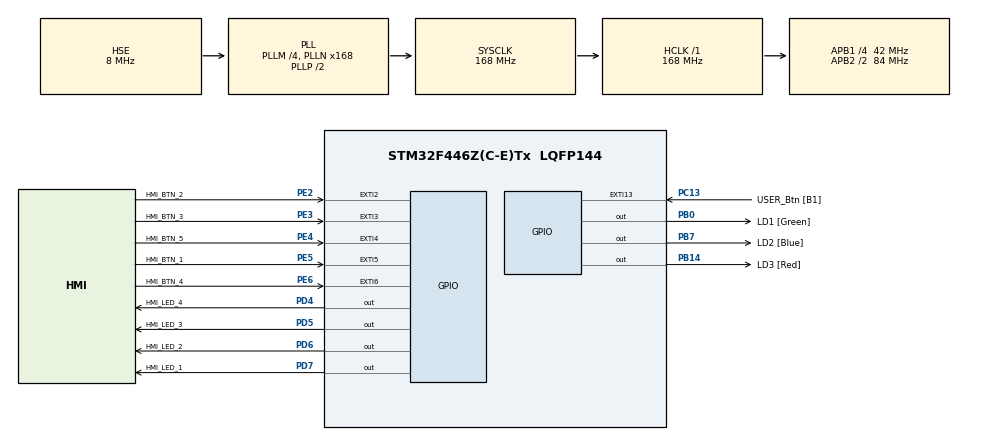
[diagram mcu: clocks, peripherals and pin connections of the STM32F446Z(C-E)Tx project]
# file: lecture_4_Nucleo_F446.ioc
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Mcu.Family=STM32F4
Mcu.Name=STM32F446Z(C-E)Tx
Mcu.Package=LQFP144
NVIC.EXTI15_10_IRQn=true\:0\:0\:false\:false\:true\:true\:true\:true
NVIC.EXTI2_IRQn=true\:0\:0\:false\:false\:true\:true\:true\:true
NVIC.EXTI3_IRQn=true\:0\:0\:false\:false\:true\:true\:true\:true
NVIC.EXTI4_IRQn=true\:0\:0\:false\:false\:true\:true\:true\:true
NVIC.EXTI9_5_IRQn=true\:0\:0\:false\:false\:true\:true\:true\:true
NVIC.PriorityGroup=NVIC_PRIORITYGROUP_4
PA13.Mode=Serial_Wire
PA13.Signal=SYS_JTMS-SWDIO
PA14.Mode=Serial_Wire
PA14.Signal=SYS_JTCK-SWCLK
PB0.GPIO_Label=LD1 [Green]
PB0.Signal=GPIO_Output
PB14.GPIO_Label=LD3 [Red]
PB14.Signal=GPIO_Output
PB7.GPIO_Label=LD2 [Blue]
PB7.Signal=GPIO_Output
PC13.GPIO_Label=USER_Btn [B1]
PC13.GPIO_ModeDefaultEXTI=GPIO_MODE_IT_RISING_FALLING
PC13.Signal=GPXTI13
PC14-OSC32_IN.Mode=LSE-External-Oscillator
PC14-OSC32_IN.Signal=RCC_OSC32_IN
PC15-OSC32_OUT.Mode=LSE-External-Oscillator
PC15-OSC32_OUT.Signal=RCC_OSC32_OUT
PD4.GPIO_Label=HMI_LED_4
PD4.GPIO_ModeDefaultOutputPP=GPIO_MODE_OUTPUT_PP
PD4.GPIO_PuPd=GPIO_NOPULL
PD4.GPIO_Speed=GPIO_SPEED_FREQ_LOW
PD4.PinState=GPIO_PIN_RESET
PD4.Signal=GPIO_Output
PD5.GPIO_Label=HMI_LED_3
PD5.GPIO_ModeDefaultOutputPP=GPIO_MODE_OUTPUT_PP
PD5.GPIO_PuPd=GPIO_NOPULL
PD5.GPIO_Speed=GPIO_SPEED_FREQ_LOW
PD5.PinState=GPIO_PIN_RESET
PD5.Signal=GPIO_Output
PD6.GPIO_Label=HMI_LED_2
PD6.GPIO_ModeDefaultOutputPP=GPIO_MODE_OUTPUT_PP
PD6.GPIO_PuPd=GPIO_NOPULL
PD6.GPIO_Speed=GPIO_SPEED_FREQ_LOW
PD6.PinState=GPIO_PIN_RESET
PD6.Signal=GPIO_Output
PD7.GPIO_Label=HMI_LED_1
PD7.GPIO_ModeDefaultOutputPP=GPIO_MODE_OUTPUT_PP
PD7.GPIO_PuPd=GPIO_NOPULL
PD7.GPIO_Speed=GPIO_SPEED_FREQ_LOW
PD7.PinState=GPIO_PIN_RESET
PD7.Signal=GPIO_Output
PE2.GPIO_Label=HMI_BTN_2
PE2.GPIO_ModeDefaultEXTI=GPIO_MODE_IT_RISING_FALLING
PE2.Signal=GPXTI2
PE3.GPIO_Label=HMI_BTN_3
PE3.GPIO_ModeDefaultEXTI=GPIO_MODE_IT_RISING_FALLING
PE3.Signal=GPXTI3
PE4.GPIO_Label=HMI_BTN_5
PE4.GPIO_ModeDefaultEXTI=GPIO_MODE_IT_RISING_FALLING
PE4.Signal=GPXTI4
PE5.GPIO_Label=HMI_BTN_1
PE5.GPIO_ModeDefaultEXTI=GPIO_MODE_IT_RISING_FALLING
PE5.Signal=GPXTI5
PE6.GPIO_Label=HMI_BTN_4
PE6.GPIO_ModeDefaultEXTI=GPIO_MODE_IT_RISING_FALLING
PE6.Signal=GPXTI6
PH0-OSC_IN.Mode=HSE-External-Clock-Source
PH0-OSC_IN.Signal=RCC_OSC_IN
PH1-OSC_OUT.Mode=HSE-External-Clock-Source
PH1-OSC_OUT.Signal=RCC_OSC_OUT
ProjectManager.HeapSize=0x200
ProjectManager.StackSize=0x400
ProjectManager.TargetToolchain=STM32CubeIDE
RCC.48MHZClocksFreq_Value=24000000
RCC.AHBFreq_Value=168000000
RCC.APB1CLKDivider=RCC_HCLK_DIV4
RCC.APB1Freq_Value=42000000
RCC.APB1TimFreq_Value=84000000
RCC.APB2CLKDivider=RCC_HCLK_DIV2
RCC.APB2Freq_Value=84000000
RCC.APB2TimFreq_Value=168000000
RCC.CortexFreq_Value=168000000
RCC.HCLKFreq_Value=168000000
RCC.HSE_VALUE=8000000
RCC.HSI_VALUE=16000000
RCC.PLLM=4
RCC.PLLMUL=RCC_PLL_MUL9
RCC.PLLN=168
RCC.PLLQ=7
RCC.PLLSourceVirtual=RCC_PLLSOURCE_HSE
RCC.PRESCALERUSB=RCC_USBCLKSOURCE_PLL_DIV1_5
RCC.SYSCLKFreq_VALUE=168000000
RCC.SYSCLKSource=RCC_SYSCLKSOURCE_PLLCLK
RCC.SYSCLKSourceVirtual=RCC_SYSCLKSOURCE_PLLCLK
RCC.USBFreq_Value=48000000
RCC.VCOOutputFreq_Value=336000000
board=NUCLEO-F446ZE

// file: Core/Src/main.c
/* USER CODE BEGIN Header */
/**
  ******************************************************************************
  * @file           : main.c
  * @brief          : Main program body
  ******************************************************************************
  * @attention
  *
  * Copyright (c) 2024 STMicroelectronics.
  * All rights reserved.
  *
  * This software is licensed under terms that can be found in the LICENSE file
  * in the root directory of this software component.
  * If no LICENSE file comes with this software, it is provided AS-IS.
  *
  ******************************************************************************
  */
/* USER CODE END Header */
#include "main.h"
#include "gpio.h"

/* USER CODE BEGIN Includes */
#include "../../External/Inc/example.h"
/* USER CODE END Includes */

void SystemClock_Config(void);

int main(void)
{
  /* MCU Configuration--------------------------------------------------------*/

  /* Reset of all peripherals, Initializes the Flash interface and the Systick. */
  HAL_Init();

  /* Configure the system clock */
  SystemClock_Config();

  /* Initialize all configured peripherals */
  MX_GPIO_Init();

  /* USER CODE BEGIN 2 */
  // 1. Regiszterek címzése és beállítása egyszer, indulás után:
  uint32_t GPIOD_base_addr = 0x40020C00;
  uint32_t RCC_base_addr = 0x40023800;
  uint32_t* GPIO_MODDER_addr= (uint32_t *)(GPIOD_base_addr+0x00);
  uint32_t* GPIO_ODR_addr = (uint32_t *)(GPIOD_base_addr+0x14);
  uint32_t* RCC_AHB1 = (uint32_t *)(RCC_base_addr+0x30);

  *RCC_AHB1 = 0x00100008;			// GPIOD órajel engedélyezése
  *GPIO_MODDER_addr = 0x00004000; 	// PD7 kimenetnek beállítva
  *GPIO_ODR_addr = 0x00000000; 		// Kezdeti állapot 0
  /* USER CODE END 2 */

  /* Infinite loop */
  /* USER CODE BEGIN WHILE */
  while (1)
  {
      *GPIO_ODR_addr = *GPIO_ODR_addr ^ 0x00000080; // PD7 toggle (XOR)
      for(uint32_t i = 0; i < 3330000; i++); 		// Késleltetés
    /* USER CODE END WHILE */

  }
}

void SystemClock_Config(void)
{
  RCC_OscInitTypeDef RCC_OscInitStruct = {0};
  RCC_ClkInitTypeDef RCC_ClkInitStruct = {0};

  /** Configure the main internal regulator output voltage
  */
  __HAL_RCC_PWR_CLK_ENABLE();
  __HAL_PWR_VOLTAGESCALING_CONFIG(PWR_REGULATOR_VOLTAGE_SCALE1);

  /** Initializes the RCC Oscillators according to the specified parameters
  * in the RCC_OscInitTypeDef structure.
  */
  RCC_OscInitStruct.OscillatorType = RCC_OSCILLATORTYPE_HSE;
  RCC_OscInitStruct.HSEState = RCC_HSE_BYPASS;
  RCC_OscInitStruct.PLL.PLLState = RCC_PLL_ON;
  RCC_OscInitStruct.PLL.PLLSource = RCC_PLLSOURCE_HSE;
  RCC_OscInitStruct.PLL.PLLM = 4;
  RCC_OscInitStruct.PLL.PLLN = 168;
  RCC_OscInitStruct.PLL.PLLP = RCC_PLLP_DIV2;
  RCC_OscInitStruct.PLL.PLLQ = 7;
  RCC_OscInitStruct.PLL.PLLR = 2;
  if (HAL_RCC_OscConfig(&RCC_OscInitStruct) != HAL_OK)
  {
    Error_Handler();
  }

  /** Initializes the CPU, AHB and APB buses clocks
  */
  RCC_ClkInitStruct.ClockType = RCC_CLOCKTYPE_HCLK|RCC_CLOCKTYPE_SYSCLK
                              |RCC_CLOCKTYPE_PCLK1|RCC_CLOCKTYPE_PCLK2;
  RCC_ClkInitStruct.SYSCLKSource = RCC_SYSCLKSOURCE_PLLCLK;
  RCC_ClkInitStruct.AHBCLKDivider = RCC_SYSCLK_DIV1;
  RCC_ClkInitStruct.APB1CLKDivider = RCC_HCLK_DIV4;
  RCC_ClkInitStruct.APB2CLKDivider = RCC_HCLK_DIV2;

  if (HAL_RCC_ClockConfig(&RCC_ClkInitStruct, FLASH_LATENCY_5) != HAL_OK)
  {
    Error_Handler();
  }
}

void Error_Handler(void)
{
  __disable_irq();
  while (1)
  {
  }
}
